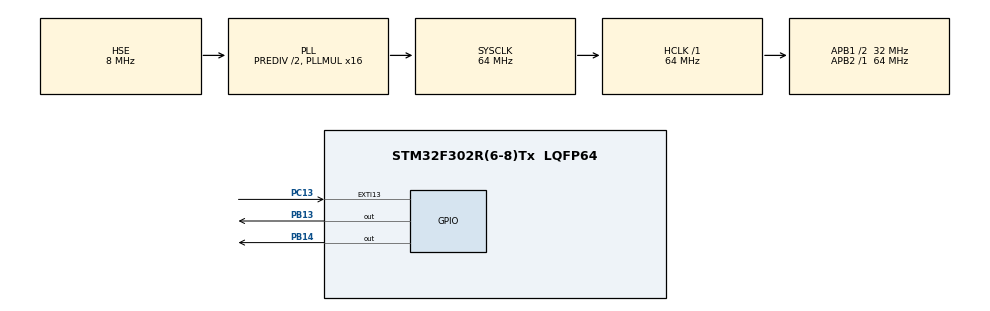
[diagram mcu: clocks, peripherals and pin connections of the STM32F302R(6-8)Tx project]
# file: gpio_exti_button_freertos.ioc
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FREERTOS.Tasks01=defaultTask,0,128,StartDefaultTask,Default,NULL,Dynamic,NULL,NULL
FREERTOS.configUSE_NEWLIB_REENTRANT=1
Mcu.Family=STM32F3
Mcu.Name=STM32F302R(6-8)Tx
Mcu.Package=LQFP64
NVIC.EXTI15_10_IRQn=true\:5\:0\:false\:false\:true\:true\:true\:true\:true
NVIC.PriorityGroup=NVIC_PRIORITYGROUP_4
NVIC.TIM6_DAC_IRQn=true\:15\:0\:false\:false\:true\:false\:false\:true\:true
NVIC.TimeBase=TIM6_DAC_IRQn
NVIC.TimeBaseIP=TIM6
PB13.Signal=GPIO_Output
PB14.Signal=GPIO_Output
PC13.Signal=GPXTI13
PF0-OSC_IN.Mode=HSE-External-Oscillator
PF0-OSC_IN.Signal=RCC_OSC_IN
PF1-OSC_OUT.Mode=HSE-External-Oscillator
PF1-OSC_OUT.Signal=RCC_OSC_OUT
ProjectManager.HeapSize=0x200
ProjectManager.StackSize=0x400
ProjectManager.TargetToolchain=STM32CubeIDE
RCC.AHBFreq_Value=64000000
RCC.APB1CLKDivider=RCC_HCLK_DIV2
RCC.APB1Freq_Value=32000000
RCC.APB1TimFreq_Value=64000000
RCC.APB2Freq_Value=64000000
RCC.APB2TimFreq_Value=64000000
RCC.CortexFreq_Value=64000000
RCC.HCLKFreq_Value=64000000
RCC.HSE_VALUE=8000000
RCC.HSI_VALUE=8000000
RCC.PLLM=8
RCC.PLLMUL=RCC_PLL_MUL16
RCC.PLLN=336
RCC.PLLP=RCC_PLLP_DIV4
RCC.PLLQ=7
RCC.PLLSourceVirtual=RCC_PLLSOURCE_HSE
RCC.RCC_PLLsource_Clock_Source_FROM_HSE=RCC_HSE_PREDIV_DIV2
RCC.SYSCLKFreq_VALUE=64000000
RCC.SYSCLKSourceVirtual=RCC_SYSCLKSOURCE_PLLCLK
RCC.USBFreq_Value=64000000
VP_FREERTOS_VS_CMSIS_V1.Mode=CMSIS_V1
VP_SYS_VS_tim6.Mode=TIM6
board=NUCLEO-F302R8

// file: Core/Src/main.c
/* USER CODE BEGIN Header */
/**
  ******************************************************************************
  * @file           : main.c
  * @brief          : Main program body
  ******************************************************************************
  * @attention
  *
  * Copyright (c) 2024 STMicroelectronics.
  * All rights reserved.
  *
  * This software is licensed under terms that can be found in the LICENSE file
  * in the root directory of this software component.
  * If no LICENSE file comes with this software, it is provided AS-IS.
  *
  ******************************************************************************
  */
/* USER CODE END Header */
#include "main.h"

/* USER CODE BEGIN Includes */
#include "FreeRTOS.h"
#include "task.h"
#include "timers.h"
#include "queue.h"
#include "semphr.h"
#include "event_groups.h"

#include "stdlib.h"
#include "string.h"
/* USER CODE END Includes */

void SystemClock_Config(void);
static void MX_GPIO_Init(void);

/* USER CODE BEGIN 0 */

uint8_t flag=0;
TaskHandle_t button_handler;
void button_task(void *pvParameters);

TaskHandle_t gpio_handler;
void led_task(void *pvParamters);

void HAL_GPIO_EXTI_Callback(uint16_t GPIO_Pin)
{

	  if (GPIO_Pin == GPIO_PIN_13) // Ensure it's the correct pin
	    {
	        flag = !flag; // Toggle the flag between 0 and 1
	    }
}
/* USER CODE END 0 */

int main(void)
{

  /* MCU Configuration--------------------------------------------------------*/

  /* Reset of all peripherals, Initializes the Flash interface and the Systick. */
  HAL_Init();

  /* Configure the system clock */
  SystemClock_Config();

  /* Initialize all configured peripherals */
  MX_GPIO_Init();
  /* USER CODE BEGIN 2 */
xTaskCreate(button_task, "button", 128, NULL, 3, &button_handler);
xTaskCreate(led_task, "led", 128, NULL, 2, &gpio_handler);

vTaskStartScheduler();
  /* USER CODE END 2 */

  /* Create the thread(s) */
  /* definition and creation of defaultTask */

  /* Start scheduler */

  /* We should never get here as control is now taken by the scheduler */

  /* Infinite loop */
  while (1)
  {

  }
}

void SystemClock_Config(void)
{
  RCC_OscInitTypeDef RCC_OscInitStruct = {0};
  RCC_ClkInitTypeDef RCC_ClkInitStruct = {0};

  /** Initializes the RCC Oscillators according to the specified parameters
  * in the RCC_OscInitTypeDef structure.
  */
  RCC_OscInitStruct.OscillatorType = RCC_OSCILLATORTYPE_HSE;
  RCC_OscInitStruct.HSEState = RCC_HSE_ON;
  RCC_OscInitStruct.HSEPredivValue = RCC_HSE_PREDIV_DIV2;
  RCC_OscInitStruct.HSIState = RCC_HSI_ON;
  RCC_OscInitStruct.PLL.PLLState = RCC_PLL_ON;
  RCC_OscInitStruct.PLL.PLLSource = RCC_PLLSOURCE_HSE;
  RCC_OscInitStruct.PLL.PLLMUL = RCC_PLL_MUL16;
  if (HAL_RCC_OscConfig(&RCC_OscInitStruct) != HAL_OK)
  {
    Error_Handler();
  }

  /** Initializes the CPU, AHB and APB buses clocks
  */
  RCC_ClkInitStruct.ClockType = RCC_CLOCKTYPE_HCLK|RCC_CLOCKTYPE_SYSCLK
                              |RCC_CLOCKTYPE_PCLK1|RCC_CLOCKTYPE_PCLK2;
  RCC_ClkInitStruct.SYSCLKSource = RCC_SYSCLKSOURCE_PLLCLK;
  RCC_ClkInitStruct.AHBCLKDivider = RCC_SYSCLK_DIV1;
  RCC_ClkInitStruct.APB1CLKDivider = RCC_HCLK_DIV2;
  RCC_ClkInitStruct.APB2CLKDivider = RCC_HCLK_DIV1;

  if (HAL_RCC_ClockConfig(&RCC_ClkInitStruct, FLASH_LATENCY_2) != HAL_OK)
  {
    Error_Handler();
  }
}

static void MX_GPIO_Init(void)
{
  GPIO_InitTypeDef GPIO_InitStruct = {0};

  /* GPIO Ports Clock Enable */
  __HAL_RCC_GPIOC_CLK_ENABLE();
  __HAL_RCC_GPIOF_CLK_ENABLE();
  __HAL_RCC_GPIOB_CLK_ENABLE();

  /*Configure GPIO pin Output Level */
  HAL_GPIO_WritePin(GPIOB, GPIO_PIN_13|GPIO_PIN_14, GPIO_PIN_RESET);

  /*Configure GPIO pin : PC13 */
  GPIO_InitStruct.Pin = GPIO_PIN_13;
  GPIO_InitStruct.Mode = GPIO_MODE_IT_RISING;
  GPIO_InitStruct.Pull = GPIO_NOPULL;
  HAL_GPIO_Init(GPIOC, &GPIO_InitStruct);

  /*Configure GPIO pins : PB13 PB14 */
  GPIO_InitStruct.Pin = GPIO_PIN_13|GPIO_PIN_14;
  GPIO_InitStruct.Mode = GPIO_MODE_OUTPUT_PP;
  GPIO_InitStruct.Pull = GPIO_NOPULL;
  GPIO_InitStruct.Speed = GPIO_SPEED_FREQ_LOW;
  HAL_GPIO_Init(GPIOB, &GPIO_InitStruct);

  /* EXTI interrupt init*/
  HAL_NVIC_SetPriority(EXTI15_10_IRQn, 5, 0);
  HAL_NVIC_EnableIRQ(EXTI15_10_IRQn);

}

/* USER CODE BEGIN 4 */
void button_task(void *pvParameters)
{
	TickType_t time= xTaskGetTickCount();
	while(1)
	{
		if((xTaskGetTickCount()-time)>200)
		{
			time=xTaskGetTickCount();
			HAL_GPIO_TogglePin(GPIOB, GPIO_PIN_14);
		}
		vTaskDelay(pdMS_TO_TICKS(1));
	}
}

void led_task(void *pvParameters)
{
	while(1)
	{
		if(flag)
		{
			HAL_GPIO_WritePin(GPIOB, GPIO_PIN_13, GPIO_PIN_SET);
		}
		else
		{
			HAL_GPIO_WritePin(GPIOB, GPIO_PIN_13, GPIO_PIN_RESET);
		}
		vTaskDelay(pdMS_TO_TICKS(1));
	}
}
/* USER CODE END 4 */

void HAL_TIM_PeriodElapsedCallback(TIM_HandleTypeDef *htim)
{
  if (htim->Instance == TIM6) {
    HAL_IncTick();
  }
}

void Error_Handler(void)
{
  __disable_irq();
  while (1)
  {
  }
}
